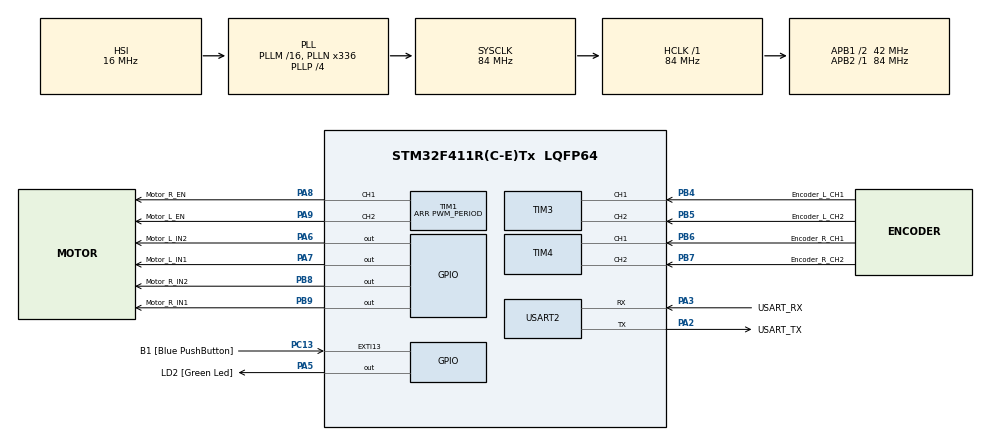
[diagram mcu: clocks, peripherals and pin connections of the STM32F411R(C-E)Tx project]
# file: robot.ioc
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Dma.Request0=USART2_RX
Dma.Request1=USART2_TX
Dma.USART2_RX.0.Direction=DMA_PERIPH_TO_MEMORY
Dma.USART2_RX.0.FIFOMode=DMA_FIFOMODE_DISABLE
Dma.USART2_RX.0.Instance=DMA1_Stream5
Dma.USART2_RX.0.MemDataAlignment=DMA_MDATAALIGN_BYTE
Dma.USART2_RX.0.MemInc=DMA_MINC_ENABLE
Dma.USART2_RX.0.Mode=DMA_NORMAL
Dma.USART2_RX.0.PeriphDataAlignment=DMA_PDATAALIGN_BYTE
Dma.USART2_RX.0.PeriphInc=DMA_PINC_DISABLE
Dma.USART2_RX.0.Priority=DMA_PRIORITY_HIGH
Dma.USART2_TX.1.Direction=DMA_MEMORY_TO_PERIPH
Dma.USART2_TX.1.FIFOMode=DMA_FIFOMODE_DISABLE
Dma.USART2_TX.1.Instance=DMA1_Stream6
Dma.USART2_TX.1.MemDataAlignment=DMA_MDATAALIGN_BYTE
Dma.USART2_TX.1.MemInc=DMA_MINC_ENABLE
Dma.USART2_TX.1.Mode=DMA_NORMAL
Dma.USART2_TX.1.PeriphDataAlignment=DMA_PDATAALIGN_BYTE
Dma.USART2_TX.1.PeriphInc=DMA_PINC_DISABLE
Dma.USART2_TX.1.Priority=DMA_PRIORITY_HIGH
Mcu.Family=STM32F4
Mcu.Name=STM32F411R(C-E)Tx
Mcu.Package=LQFP64
Mcu.UserConstants=ENCODER_PERIOD,0xFFFF;ENCODER_RELOAD,(ENCODER_PERIOD / 2);PWM_FREQ,24000;PWM_PERIOD,(CLOCK_FREQ / PWM_FREQ - 1);CLOCK_FREQ,84000000
NVIC.DMA1_Stream5_IRQn=true\:0\:0\:false\:false\:true\:false\:true
NVIC.DMA1_Stream6_IRQn=true\:0\:0\:false\:false\:true\:false\:true
NVIC.PriorityGroup=NVIC_PRIORITYGROUP_0
NVIC.USART2_IRQn=true\:0\:0\:false\:false\:true\:true\:true
PA13.GPIO_Label=TMS
PA13.Mode=Serial_Wire
PA13.Signal=SYS_JTMS-SWDIO
PA14.GPIO_Label=TCK
PA14.Mode=Serial_Wire
PA14.Signal=SYS_JTCK-SWCLK
PA2.GPIO_Label=USART_TX
PA2.Mode=Asynchronous
PA2.Signal=USART2_TX
PA3.GPIO_Label=USART_RX
PA3.Mode=Asynchronous
PA3.Signal=USART2_RX
PA5.GPIO_Label=LD2 [Green Led]
PA5.Signal=GPIO_Output
PA6.GPIO_Label=Motor_L_IN2
PA6.GPIO_PuPd=GPIO_PULLDOWN
PA6.Signal=GPIO_Output
PA7.GPIO_Label=Motor_L_IN1
PA7.GPIO_PuPd=GPIO_PULLDOWN
PA7.Signal=GPIO_Output
PA8.GPIO_Label=Motor_R_EN
PA8.GPIO_PuPd=GPIO_PULLDOWN
PA8.Signal=S_TIM1_CH1
PA9.GPIO_Label=Motor_L_EN
PA9.GPIO_PuPd=GPIO_PULLDOWN
PA9.Signal=S_TIM1_CH2
PB3.GPIO_Label=SWO
PB3.Signal=SYS_JTDO-SWO
PB4.GPIO_Label=Encoder_L_CH1
PB4.GPIO_PuPd=GPIO_PULLUP
PB4.Signal=S_TIM3_CH1
PB5.GPIO_Label=Encoder_L_CH2
PB5.GPIO_PuPd=GPIO_PULLUP
PB5.Signal=S_TIM3_CH2
PB6.GPIO_Label=Encoder_R_CH1
PB6.GPIO_PuPd=GPIO_PULLUP
PB6.Signal=S_TIM4_CH1
PB7.GPIO_Label=Encoder_R_CH2
PB7.GPIO_PuPd=GPIO_PULLUP
PB7.Signal=S_TIM4_CH2
PB8.GPIO_Label=Motor_R_IN2
PB8.GPIO_PuPd=GPIO_PULLDOWN
PB8.Signal=GPIO_Output
PB9.GPIO_Label=Motor_R_IN1
PB9.GPIO_PuPd=GPIO_PULLDOWN
PB9.Signal=GPIO_Output
PC13-ANTI_TAMP.GPIO_Label=B1 [Blue PushButton]
PC13-ANTI_TAMP.GPIO_ModeDefaultEXTI=GPIO_MODE_IT_FALLING
PC13-ANTI_TAMP.Signal=GPXTI13
PC14-OSC32_IN.Mode=LSE-External-Oscillator
PC14-OSC32_IN.Signal=RCC_OSC32_IN
PC15-OSC32_OUT.Mode=LSE-External-Oscillator
PC15-OSC32_OUT.Signal=RCC_OSC32_OUT
PH0\ -\ OSC_IN.Mode=HSE-External-Clock-Source
PH0\ -\ OSC_IN.Signal=RCC_OSC_IN
PH1\ -\ OSC_OUT.Mode=HSE-External-Clock-Source
PH1\ -\ OSC_OUT.Signal=RCC_OSC_OUT
ProjectManager.HeapSize=0x200
ProjectManager.StackSize=0x400
ProjectManager.TargetToolchain=STM32CubeIDE
RCC.48MHZClocksFreq_Value=84000000
RCC.AHBFreq_Value=84000000
RCC.APB1CLKDivider=RCC_HCLK_DIV2
RCC.APB1Freq_Value=42000000
RCC.APB1TimFreq_Value=84000000
RCC.APB2Freq_Value=84000000
RCC.APB2TimFreq_Value=84000000
RCC.CortexFreq_Value=84000000
RCC.FLatency-AdvancedSettings=FLASH_LATENCY_2
RCC.HCLKFreq_Value=84000000
RCC.HSE_VALUE=8000000
RCC.HSI_VALUE=16000000
RCC.PLLN=336
RCC.PLLP=RCC_PLLP_DIV4
RCC.SYSCLKFreq_VALUE=84000000
RCC.SYSCLKSource=RCC_SYSCLKSOURCE_PLLCLK
RCC.VCOOutputFreq_Value=336000000
SH.S_TIM1_CH1.0=TIM1_CH1,PWM Generation1 CH1
SH.S_TIM1_CH2.0=TIM1_CH2,PWM Generation2 CH2
SH.S_TIM3_CH1.0=TIM3_CH1,Encoder_Interface
SH.S_TIM3_CH2.0=TIM3_CH2,Encoder_Interface
SH.S_TIM4_CH1.0=TIM4_CH1,Encoder_Interface
SH.S_TIM4_CH2.0=TIM4_CH2,Encoder_Interface
TIM1.Channel-PWM\ Generation1\ CH1=TIM_CHANNEL_1
TIM1.Channel-PWM\ Generation2\ CH2=TIM_CHANNEL_2
TIM1.Period=PWM_PERIOD
TIM3.EncoderMode=TIM_ENCODERMODE_TI12
TIM3.Period=ENCODER_PERIOD
TIM4.EncoderMode=TIM_ENCODERMODE_TI12
TIM4.Period=ENCODER_PERIOD
USART2.VirtualMode=VM_ASYNC
board=NUCLEO-F411RE

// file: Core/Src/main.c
/* USER CODE BEGIN Header */
/**
  ******************************************************************************
  * @file           : main.c
  * @brief          : Main program body
  ******************************************************************************
  ******************************************************************************
  */
/* USER CODE END Header */

#include "main.h"

/* USER CODE BEGIN Includes */
#include "mainpp.h"
/* USER CODE END Includes */

TIM_HandleTypeDef htim1;
TIM_HandleTypeDef htim3;
TIM_HandleTypeDef htim4;

UART_HandleTypeDef huart2;
DMA_HandleTypeDef hdma_usart2_rx;
DMA_HandleTypeDef hdma_usart2_tx;

void SystemClock_Config(void);
static void MX_GPIO_Init(void);
static void MX_USART2_UART_Init(void);
static void MX_TIM3_Init(void);
static void MX_DMA_Init(void);
static void MX_TIM1_Init(void);
static void MX_TIM4_Init(void);

/* USER CODE BEGIN 0 */
/**
 * @brief  Retargets the C library printf function to the USART.
 */
int __io_putchar(int ch) {
  HAL_UART_Transmit(&huart2, (uint8_t *)&ch, 1, 0xFFFF);
  return ch;
}

/* USER CODE END 0 */

int main(void)
{

  /* MCU Configuration--------------------------------------------------------*/

  /* Reset of all peripherals, Initializes the Flash interface and the Systick. */
  HAL_Init();

  /* USER CODE BEGIN Init */
  MX_DMA_Init();
  /* USER CODE END Init */

  /* Configure the system clock */
  SystemClock_Config();

  /* Initialize all configured peripherals */
  MX_GPIO_Init();
  MX_USART2_UART_Init();
  MX_TIM3_Init();
  MX_DMA_Init();
  MX_TIM1_Init();
  MX_TIM4_Init();
  /* USER CODE BEGIN 2 */
  setup();
  /* USER CODE END 2 */

  /* Infinite loop */
  while (1)
  {

    /* USER CODE BEGIN 3 */
    loop();
  }
  /* USER CODE END 3 */
}

void SystemClock_Config(void)
{
  RCC_OscInitTypeDef RCC_OscInitStruct = {0};
  RCC_ClkInitTypeDef RCC_ClkInitStruct = {0};

  /** Configure the main internal regulator output voltage
  */
  __HAL_RCC_PWR_CLK_ENABLE();
  __HAL_PWR_VOLTAGESCALING_CONFIG(PWR_REGULATOR_VOLTAGE_SCALE1);
  /** Initializes the CPU, AHB and APB busses clocks
  */
  RCC_OscInitStruct.OscillatorType = RCC_OSCILLATORTYPE_HSI;
  RCC_OscInitStruct.HSIState = RCC_HSI_ON;
  RCC_OscInitStruct.HSICalibrationValue = RCC_HSICALIBRATION_DEFAULT;
  RCC_OscInitStruct.PLL.PLLState = RCC_PLL_ON;
  RCC_OscInitStruct.PLL.PLLSource = RCC_PLLSOURCE_HSI;
  RCC_OscInitStruct.PLL.PLLM = 16;
  RCC_OscInitStruct.PLL.PLLN = 336;
  RCC_OscInitStruct.PLL.PLLP = RCC_PLLP_DIV4;
  RCC_OscInitStruct.PLL.PLLQ = 4;
  if (HAL_RCC_OscConfig(&RCC_OscInitStruct) != HAL_OK)
  {
    Error_Handler();
  }
  /** Initializes the CPU, AHB and APB busses clocks
  */
  RCC_ClkInitStruct.ClockType = RCC_CLOCKTYPE_HCLK|RCC_CLOCKTYPE_SYSCLK
                              |RCC_CLOCKTYPE_PCLK1|RCC_CLOCKTYPE_PCLK2;
  RCC_ClkInitStruct.SYSCLKSource = RCC_SYSCLKSOURCE_PLLCLK;
  RCC_ClkInitStruct.AHBCLKDivider = RCC_SYSCLK_DIV1;
  RCC_ClkInitStruct.APB1CLKDivider = RCC_HCLK_DIV2;
  RCC_ClkInitStruct.APB2CLKDivider = RCC_HCLK_DIV1;

  if (HAL_RCC_ClockConfig(&RCC_ClkInitStruct, FLASH_LATENCY_2) != HAL_OK)
  {
    Error_Handler();
  }
}

static void MX_TIM1_Init(void)
{

  TIM_MasterConfigTypeDef sMasterConfig = {0};
  TIM_OC_InitTypeDef sConfigOC = {0};
  TIM_BreakDeadTimeConfigTypeDef sBreakDeadTimeConfig = {0};

  htim1.Instance = TIM1;
  htim1.Init.Prescaler = 0;
  htim1.Init.CounterMode = TIM_COUNTERMODE_UP;
  htim1.Init.Period = PWM_PERIOD;
  htim1.Init.ClockDivision = TIM_CLOCKDIVISION_DIV1;
  htim1.Init.RepetitionCounter = 0;
  htim1.Init.AutoReloadPreload = TIM_AUTORELOAD_PRELOAD_DISABLE;
  if (HAL_TIM_PWM_Init(&htim1) != HAL_OK)
  {
    Error_Handler();
  }
  sMasterConfig.MasterOutputTrigger = TIM_TRGO_RESET;
  sMasterConfig.MasterSlaveMode = TIM_MASTERSLAVEMODE_DISABLE;
  if (HAL_TIMEx_MasterConfigSynchronization(&htim1, &sMasterConfig) != HAL_OK)
  {
    Error_Handler();
  }
  sConfigOC.OCMode = TIM_OCMODE_PWM1;
  sConfigOC.Pulse = 0;
  sConfigOC.OCPolarity = TIM_OCPOLARITY_HIGH;
  sConfigOC.OCNPolarity = TIM_OCNPOLARITY_HIGH;
  sConfigOC.OCFastMode = TIM_OCFAST_DISABLE;
  sConfigOC.OCIdleState = TIM_OCIDLESTATE_RESET;
  sConfigOC.OCNIdleState = TIM_OCNIDLESTATE_RESET;
  if (HAL_TIM_PWM_ConfigChannel(&htim1, &sConfigOC, TIM_CHANNEL_1) != HAL_OK)
  {
    Error_Handler();
  }
  if (HAL_TIM_PWM_ConfigChannel(&htim1, &sConfigOC, TIM_CHANNEL_2) != HAL_OK)
  {
    Error_Handler();
  }
  sBreakDeadTimeConfig.OffStateRunMode = TIM_OSSR_DISABLE;
  sBreakDeadTimeConfig.OffStateIDLEMode = TIM_OSSI_DISABLE;
  sBreakDeadTimeConfig.LockLevel = TIM_LOCKLEVEL_OFF;
  sBreakDeadTimeConfig.DeadTime = 0;
  sBreakDeadTimeConfig.BreakState = TIM_BREAK_DISABLE;
  sBreakDeadTimeConfig.BreakPolarity = TIM_BREAKPOLARITY_HIGH;
  sBreakDeadTimeConfig.AutomaticOutput = TIM_AUTOMATICOUTPUT_DISABLE;
  if (HAL_TIMEx_ConfigBreakDeadTime(&htim1, &sBreakDeadTimeConfig) != HAL_OK)
  {
    Error_Handler();
  }
  HAL_TIM_MspPostInit(&htim1);

}

static void MX_TIM3_Init(void)
{

  TIM_Encoder_InitTypeDef sConfig = {0};
  TIM_MasterConfigTypeDef sMasterConfig = {0};

  htim3.Instance = TIM3;
  htim3.Init.Prescaler = 0;
  htim3.Init.CounterMode = TIM_COUNTERMODE_UP;
  htim3.Init.Period = ENCODER_PERIOD;
  htim3.Init.ClockDivision = TIM_CLOCKDIVISION_DIV1;
  htim3.Init.AutoReloadPreload = TIM_AUTORELOAD_PRELOAD_DISABLE;
  sConfig.EncoderMode = TIM_ENCODERMODE_TI12;
  sConfig.IC1Polarity = TIM_ICPOLARITY_RISING;
  sConfig.IC1Selection = TIM_ICSELECTION_DIRECTTI;
  sConfig.IC1Prescaler = TIM_ICPSC_DIV1;
  sConfig.IC1Filter = 0;
  sConfig.IC2Polarity = TIM_ICPOLARITY_RISING;
  sConfig.IC2Selection = TIM_ICSELECTION_DIRECTTI;
  sConfig.IC2Prescaler = TIM_ICPSC_DIV1;
  sConfig.IC2Filter = 0;
  if (HAL_TIM_Encoder_Init(&htim3, &sConfig) != HAL_OK)
  {
    Error_Handler();
  }
  sMasterConfig.MasterOutputTrigger = TIM_TRGO_RESET;
  sMasterConfig.MasterSlaveMode = TIM_MASTERSLAVEMODE_DISABLE;
  if (HAL_TIMEx_MasterConfigSynchronization(&htim3, &sMasterConfig) != HAL_OK)
  {
    Error_Handler();
  }

}

static void MX_TIM4_Init(void)
{

  TIM_Encoder_InitTypeDef sConfig = {0};
  TIM_MasterConfigTypeDef sMasterConfig = {0};

  htim4.Instance = TIM4;
  htim4.Init.Prescaler = 0;
  htim4.Init.CounterMode = TIM_COUNTERMODE_UP;
  htim4.Init.Period = ENCODER_PERIOD;
  htim4.Init.ClockDivision = TIM_CLOCKDIVISION_DIV1;
  htim4.Init.AutoReloadPreload = TIM_AUTORELOAD_PRELOAD_DISABLE;
  sConfig.EncoderMode = TIM_ENCODERMODE_TI12;
  sConfig.IC1Polarity = TIM_ICPOLARITY_RISING;
  sConfig.IC1Selection = TIM_ICSELECTION_DIRECTTI;
  sConfig.IC1Prescaler = TIM_ICPSC_DIV1;
  sConfig.IC1Filter = 0;
  sConfig.IC2Polarity = TIM_ICPOLARITY_RISING;
  sConfig.IC2Selection = TIM_ICSELECTION_DIRECTTI;
  sConfig.IC2Prescaler = TIM_ICPSC_DIV1;
  sConfig.IC2Filter = 0;
  if (HAL_TIM_Encoder_Init(&htim4, &sConfig) != HAL_OK)
  {
    Error_Handler();
  }
  sMasterConfig.MasterOutputTrigger = TIM_TRGO_RESET;
  sMasterConfig.MasterSlaveMode = TIM_MASTERSLAVEMODE_DISABLE;
  if (HAL_TIMEx_MasterConfigSynchronization(&htim4, &sMasterConfig) != HAL_OK)
  {
    Error_Handler();
  }

}

static void MX_USART2_UART_Init(void)
{

  huart2.Instance = USART2;
  huart2.Init.BaudRate = 115200;
  huart2.Init.WordLength = UART_WORDLENGTH_8B;
  huart2.Init.StopBits = UART_STOPBITS_1;
  huart2.Init.Parity = UART_PARITY_NONE;
  huart2.Init.Mode = UART_MODE_TX_RX;
  huart2.Init.HwFlowCtl = UART_HWCONTROL_NONE;
  huart2.Init.OverSampling = UART_OVERSAMPLING_16;
  if (HAL_UART_Init(&huart2) != HAL_OK)
  {
    Error_Handler();
  }

}

static void MX_DMA_Init(void)
{

  /* DMA controller clock enable */
  __HAL_RCC_DMA1_CLK_ENABLE();

  /* DMA interrupt init */
  /* DMA1_Stream5_IRQn interrupt configuration */
  HAL_NVIC_SetPriority(DMA1_Stream5_IRQn, 0, 0);
  HAL_NVIC_EnableIRQ(DMA1_Stream5_IRQn);
  /* DMA1_Stream6_IRQn interrupt configuration */
  HAL_NVIC_SetPriority(DMA1_Stream6_IRQn, 0, 0);
  HAL_NVIC_EnableIRQ(DMA1_Stream6_IRQn);

}

static void MX_GPIO_Init(void)
{
  GPIO_InitTypeDef GPIO_InitStruct = {0};

  /* GPIO Ports Clock Enable */
  __HAL_RCC_GPIOC_CLK_ENABLE();
  __HAL_RCC_GPIOH_CLK_ENABLE();
  __HAL_RCC_GPIOA_CLK_ENABLE();
  __HAL_RCC_GPIOB_CLK_ENABLE();

  /*Configure GPIO pin Output Level */
  HAL_GPIO_WritePin(GPIOA, LD2_Pin|Motor_L_IN2_Pin|Motor_L_IN1_Pin, GPIO_PIN_RESET);

  /*Configure GPIO pin Output Level */
  HAL_GPIO_WritePin(GPIOB, Motor_R_IN2_Pin|Motor_R_IN1_Pin, GPIO_PIN_RESET);

  /*Configure GPIO pin : B1_Pin */
  GPIO_InitStruct.Pin = B1_Pin;
  GPIO_InitStruct.Mode = GPIO_MODE_IT_FALLING;
  GPIO_InitStruct.Pull = GPIO_NOPULL;
  HAL_GPIO_Init(B1_GPIO_Port, &GPIO_InitStruct);

  /*Configure GPIO pin : LD2_Pin */
  GPIO_InitStruct.Pin = LD2_Pin;
  GPIO_InitStruct.Mode = GPIO_MODE_OUTPUT_PP;
  GPIO_InitStruct.Pull = GPIO_NOPULL;
  GPIO_InitStruct.Speed = GPIO_SPEED_FREQ_LOW;
  HAL_GPIO_Init(LD2_GPIO_Port, &GPIO_InitStruct);

  /*Configure GPIO pins : Motor_L_IN2_Pin Motor_L_IN1_Pin */
  GPIO_InitStruct.Pin = Motor_L_IN2_Pin|Motor_L_IN1_Pin;
  GPIO_InitStruct.Mode = GPIO_MODE_OUTPUT_PP;
  GPIO_InitStruct.Pull = GPIO_PULLDOWN;
  GPIO_InitStruct.Speed = GPIO_SPEED_FREQ_LOW;
  HAL_GPIO_Init(GPIOA, &GPIO_InitStruct);

  /*Configure GPIO pins : Motor_R_IN2_Pin Motor_R_IN1_Pin */
  GPIO_InitStruct.Pin = Motor_R_IN2_Pin|Motor_R_IN1_Pin;
  GPIO_InitStruct.Mode = GPIO_MODE_OUTPUT_PP;
  GPIO_InitStruct.Pull = GPIO_PULLDOWN;
  GPIO_InitStruct.Speed = GPIO_SPEED_FREQ_LOW;
  HAL_GPIO_Init(GPIOB, &GPIO_InitStruct);

}

void Error_Handler(void)
{
}

/************************ (C) COPYRIGHT STMicroelectronics *****END OF FILE****/
